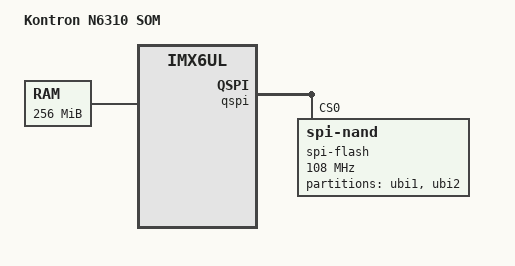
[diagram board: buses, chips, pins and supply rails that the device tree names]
// SPDX-License-Identifier: GPL-2.0
/*
 * Copyright (C) 2017 exceet electronics GmbH
 * Copyright (C) 2018 Kontron Electronics GmbH
 * Copyright (c) 2019 Krzysztof Kozlowski <krzk@kernel.org>
 */

#include "imx6ul.dtsi"
#include "imx6ul-kontron-n6x1x-som-common.dtsi"

/ {
	model = "Kontron N6310 SOM";
	compatible = "kontron,imx6ul-n6310-som", "fsl,imx6ul";

	memory@80000000 {
		reg = <0x80000000 0x10000000>;
		device_type = "memory";
	};
};

&qspi {
	spi-flash@0 {
		#address-cells = <1>;
		#size-cells = <1>;
		compatible = "spi-nand";
		spi-max-frequency = <108000000>;
		spi-tx-bus-width = <4>;
		spi-rx-bus-width = <4>;
		reg = <0>;

		partition@0 {
			label = "ubi1";
			reg = <0x00000000 0x08000000>;
		};

		partition@8000000 {
			label = "ubi2";
			reg = <0x08000000 0x08000000>;
		};
	};
};
